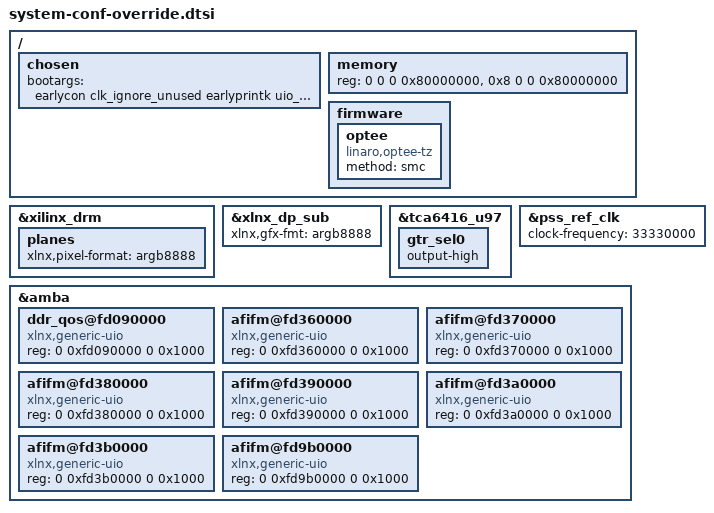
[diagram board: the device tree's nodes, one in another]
/include/ "system-conf.dtsi"

/ {
	chosen {
		bootargs = "earlycon clk_ignore_unused earlyprintk uio_pdrv_genirq.of_id=xlnx,generic-uio consoleblank=0 cma=1024M";
	};

	memory {
		device_type = "memory";
		reg = <0 0 0 0x80000000>, <0x8 0 0 0x80000000>;
	};

	firmware {
		optee {
			compatible = "linaro,optee-tz";
			method = "smc";
		};
	};
};

&xilinx_drm {
	planes {
		xlnx,pixel-format = "argb8888";
	};
};

&xlnx_dp_sub {
	xlnx,gfx-fmt = "argb8888";
};

&tca6416_u97 {
	gtr_sel0 {
		/* PCIE = 0, DP = 1 */
		/delete-property/ output-low;
		output-high;
	};
};

&pss_ref_clk {
	clock-frequency = <33330000>;
};

&amba {
	ddr_qos@fd090000 {
		compatible = "xlnx,generic-uio";
		reg = <0 0xfd090000 0 0x1000>;
	};

	afifm@fd360000 {
		compatible = "xlnx,generic-uio";
		reg = <0 0xfd360000 0 0x1000>;
	};

	afifm@fd370000 {
		compatible = "xlnx,generic-uio";
		reg = <0 0xfd370000 0 0x1000>;
	};

	afifm@fd380000 {
		compatible = "xlnx,generic-uio";
		reg = <0 0xfd380000 0 0x1000>;
	};

	afifm@fd390000 {
		compatible = "xlnx,generic-uio";
		reg = <0 0xfd390000 0 0x1000>;
	};

	afifm@fd3a0000 {
		compatible = "xlnx,generic-uio";
		reg = <0 0xfd3a0000 0 0x1000>;
	};

	afifm@fd3b0000 {
		compatible = "xlnx,generic-uio";
		reg = <0 0xfd3b0000 0 0x1000>;
	};

	afifm@fd9b0000 {
		compatible = "xlnx,generic-uio";
		reg = <0 0xfd9b0000 0 0x1000>;
	};
};
